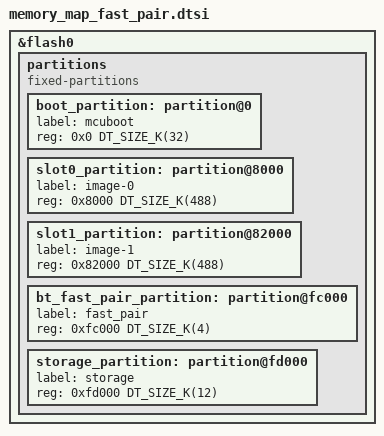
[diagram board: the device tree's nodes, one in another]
/*
 * Copyright (c) 2026 Nordic Semiconductor ASA
 *
 * SPDX-License-Identifier: LicenseRef-Nordic-5-Clause
 */

&flash0 {
	/delete-node/ partitions;

	partitions {
		compatible = "fixed-partitions";
		#address-cells = <1>;
		#size-cells = <1>;

		boot_partition: partition@0 {
			label = "mcuboot";
			reg = <0x0 DT_SIZE_K(32)>;
		};

		slot0_partition: partition@8000 {
			label = "image-0";
			reg = <0x8000 DT_SIZE_K(488)>;
		};

		slot1_partition: partition@82000 {
			label = "image-1";
			reg = <0x82000 DT_SIZE_K(488)>;
		};

		bt_fast_pair_partition: partition@fc000 {
			label = "fast_pair";
			reg = <0xfc000 DT_SIZE_K(4)>;
		};

		storage_partition: partition@fd000 {
			label = "storage";
			reg = <0xfd000 DT_SIZE_K(12)>;
		};
	};
};
